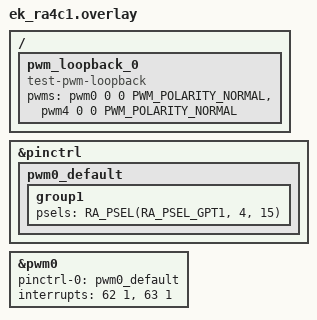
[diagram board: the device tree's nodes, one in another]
/*
 * Copyright (c) 2025 Renesas Electronics Corporation
 *
 * SPDX-License-Identifier: Apache-2.0
 */

#include <zephyr/dt-bindings/pwm/pwm.h>
#include <zephyr/dt-bindings/pwm/ra_pwm.h>

/ {
	pwm_loopback_0 {
		compatible = "test-pwm-loopback";
		pwms = <&pwm0 0 0 PWM_POLARITY_NORMAL>,
		       <&pwm4 0 0 PWM_POLARITY_NORMAL>;
	};
};

&pinctrl {
	pwm0_default: pwm0_default {
		group1 {
			/* GTIOC0A*/
			psels = <RA_PSEL(RA_PSEL_GPT1, 4, 15)>;
		};
	};
};

&pwm0 {
	pinctrl-0 = <&pwm0_default>;
	pinctrl-names = "default";
	interrupts = <62 1>, <63 1>;
	interrupt-names = "gtioca", "overflow";
	status = "okay";
};
